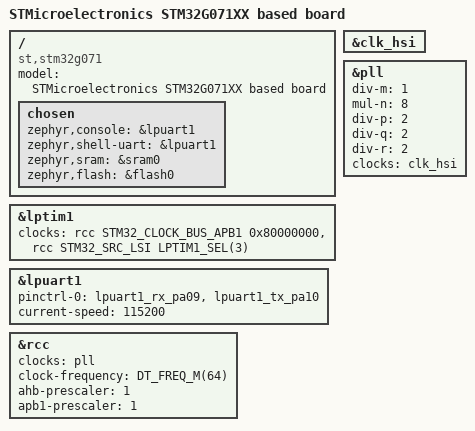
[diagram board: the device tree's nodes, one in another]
/*
 * Copyright (c) 2024 Klaus Nagel, <nagelkl01@gmail.com>
 *
 * SPDX-License-Identifier: Apache-2.0
 */

/dts-v1/;
#include <st/g0/stm32g071Xb.dtsi>
#include "stm32g071xx-pinctrl.dtsi"

/ {
	model = "STMicroelectronics STM32G071XX based board";
	compatible = "st,stm32g071", "st,stm32g0", "simple-bus";

	chosen {
		zephyr,console = &lpuart1;
		zephyr,shell-uart = &lpuart1;
		zephyr,sram = &sram0;
		zephyr,flash = &flash0;
	};
};

stm32_lp_tick_source: &lptim1 {
	clocks = <&rcc STM32_CLOCK_BUS_APB1 0x80000000>,
			 <&rcc STM32_SRC_LSI LPTIM1_SEL(3)>;
	status = "okay";
};

&lpuart1 {
	pinctrl-0 = <&lpuart1_rx_pa09 &lpuart1_tx_pa10>;
	pinctrl-names = "default";
	current-speed = <115200>;
	status = "okay";
};

&clk_hsi {
	status = "okay";
};

&pll {
	div-m = <1>;
	mul-n = <8>;
	div-p = <2>;
	div-q = <2>;
	div-r = <2>;
	clocks = <&clk_hsi>;
	status = "okay";
};

&rcc {
	clocks = <&pll>;
	clock-frequency = <DT_FREQ_M(64)>;
	ahb-prescaler = <1>;
	apb1-prescaler = <1>;
};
